# STM32L4x3 register map
File version: 1.5
CPU: CM4 r0p1, little endian, MPU, FPU, 4 interrupt priority bits
Registers are 32-bit, read-write, reset 0x0 unless marked. A register's access mark holds for its fields unless they carry their own. Offsets are from the block's base; [hi:lo] are bit positions; {n}, {i} and the like mark numbered series.

## CRS — Clock recovery system
Base 0x40006000
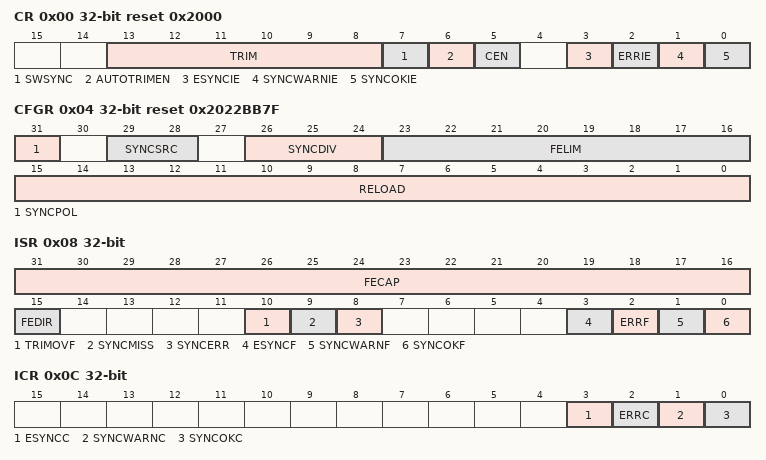
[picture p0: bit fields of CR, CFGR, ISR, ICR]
0x00 CR reset 0x2000 — control register
  [13:8] TRIM — HSI48 oscillator smooth trimming
  [7] SWSYNC — Generate software SYNC event
  [6] AUTOTRIMEN — Automatic trimming enable
  [5] CEN — Frequency error counter enable
  [3] ESYNCIE — Expected SYNC interrupt enable
  [2] ERRIE — Synchronization or trimming error interrupt enable
  [1] SYNCWARNIE — SYNC warning interrupt enable
  [0] SYNCOKIE — SYNC event OK interrupt enable
0x04 CFGR reset 0x2022BB7F — configuration register
  [31] SYNCPOL — SYNC polarity selection
  [29:28] SYNCSRC — SYNC signal source selection
  [26:24] SYNCDIV — SYNC divider
  [23:16] FELIM — Frequency error limit
  [15:0] RELOAD — Counter reload value
0x08 ISR ro — interrupt and status register
  [31:16] FECAP — Frequency error capture
  [15] FEDIR — Frequency error direction
  [10] TRIMOVF — Trimming overflow or underflow
  [9] SYNCMISS — SYNC missed
  [8] SYNCERR — SYNC error
  [3] ESYNCF — Expected SYNC flag
  [2] ERRF — Error flag
  [1] SYNCWARNF — SYNC warning flag
  [0] SYNCOKF — SYNC event OK flag
0x0C ICR — interrupt flag clear register
  [3] ESYNCC — Expected SYNC clear flag
  [2] ERRC — Error clear flag
  [1] SYNCWARNC — SYNC warning clear flag
  [0] SYNCOKC — SYNC event OK clear flag

## USB — Universal serial bus full-speed device interface
Base 0x40006C00
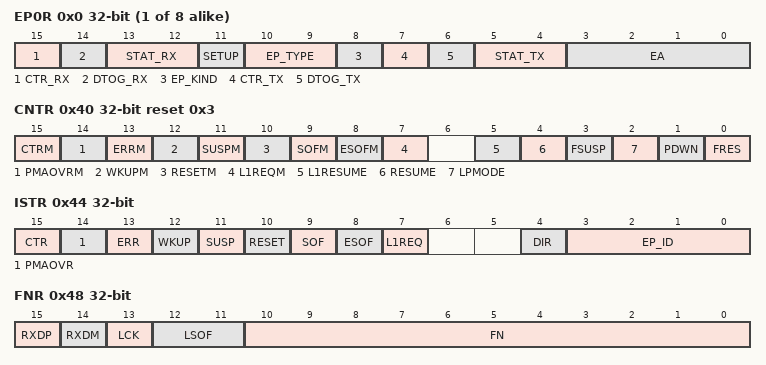
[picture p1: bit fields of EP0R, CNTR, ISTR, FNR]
{0x0+4i} EP{i}R (i=0..7) — endpoint {i} register
  [15] CTR_RX — Correct transfer for reception
  [14] DTOG_RX — Data Toggle, for reception transfers
  [13:12] STAT_RX — Status bits, for reception transfers
  [11] SETUP — Setup transaction completed
  [10:9] EP_TYPE — Endpoint type
  [8] EP_KIND — Endpoint kind
  [7] CTR_TX — Correct Transfer for transmission
  [6] DTOG_TX — Data Toggle, for transmission transfers
  [5:4] STAT_TX — Status bits, for transmission transfers
  [3:0] EA — Endpoint address
0x40 CNTR reset 0x3 — control register
  [15] CTRM — Correct transfer interrupt mask
  [14] PMAOVRM — Packet memory area over / underrun interrupt mask
  [13] ERRM — Error interrupt mask
  [12] WKUPM — Wakeup interrupt mask
  [11] SUSPM — Suspend mode interrupt mask
  [10] RESETM — USB reset interrupt mask
  [9] SOFM — Start of frame interrupt mask
  [8] ESOFM — Expected start of frame interrupt mask
  [7] L1REQM — LPM L1 state request interrupt mask
  [5] L1RESUME — LPM L1 Resume request
  [4] RESUME — Resume request
  [3] FSUSP — Force suspend
  [2] LPMODE — Low-power mode
  [1] PDWN — Power down
  [0] FRES — Force USB Reset
0x44 ISTR access per field — interrupt status register
  [15] CTR ro — Correct transfer
  [14] PMAOVR rw — Packet memory area over / underrun
  [13] ERR rw — Error
  [12] WKUP rw — Wakeup
  [11] SUSP rw — Suspend mode request
  [10] RESET rw — reset request
  [9] SOF rw — start of frame
  [8] ESOF rw — Expected start frame
  [7] L1REQ rw — LPM L1 state request
  [4] DIR ro — Direction of transaction
  [3:0] EP_ID ro — Endpoint Identifier
0x48 FNR ro — frame number register
  [15] RXDP — Receive data + line status
  [14] RXDM — Receive data - line status
  [13] LCK — Locked
  [12:11] LSOF — Lost SOF
  [10:0] FN — Frame number
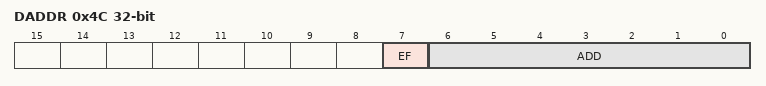
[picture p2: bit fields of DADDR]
0x4C DADDR — device address
  [7] EF — Enable function
  [6:0] ADD — Device address
0x50 BTABLE — Buffer table address
  [15:3] BTABLE — Buffer table

## DBGMCU — MCU debug component
Base 0xE0042000
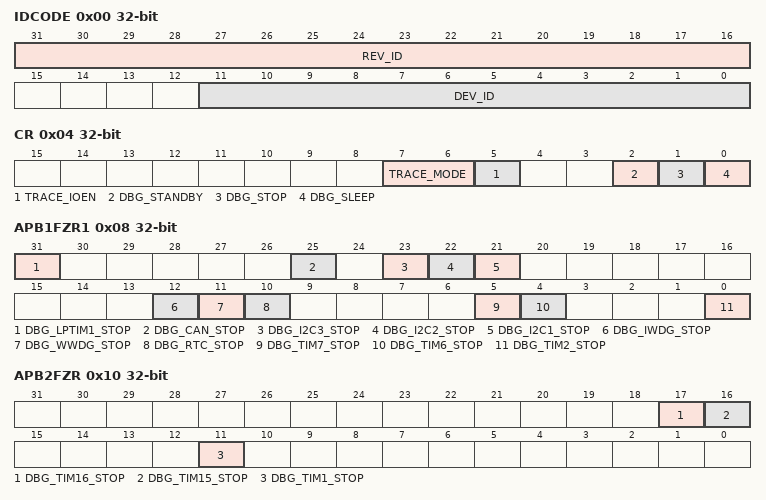
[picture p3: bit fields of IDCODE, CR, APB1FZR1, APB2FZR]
0x00 IDCODE ro — DBGMCU_IDCODE
  [31:16] REV_ID — Revision identifie
  [11:0] DEV_ID — Device identifier
0x04 CR — Debug MCU configuration register
  [7:6] TRACE_MODE — Trace pin assignment control
  [5] TRACE_IOEN — Trace pin assignment control
  [2] DBG_STANDBY — Debug Standby mode
  [1] DBG_STOP — Debug Stop mode
  [0] DBG_SLEEP — Debug Sleep mode
0x08 APB1FZR1 — Debug MCU APB1 freeze register1
  [31] DBG_LPTIM1_STOP — LPTIM1 counter stopped when core is halted
  [25] DBG_CAN_STOP — bxCAN stopped when core is halted
  [23] DBG_I2C3_STOP — I2C3 SMBUS timeout counter stopped when core is halted
  [22] DBG_I2C2_STOP — I2C2 SMBUS timeout counter stopped when core is halted
  [21] DBG_I2C1_STOP — I2C1 SMBUS timeout counter stopped when core is halted
  [12] DBG_IWDG_STOP — Independent watchdog counter stopped when core is halted
  [11] DBG_WWDG_STOP — Window watchdog counter stopped when core is halted
  [10] DBG_RTC_STOP — RTC counter stopped when core is halted
  [5] DBG_TIM7_STOP — TIM7 counter stopped when core is halted
  [4] DBG_TIM6_STOP — TIM6 counter stopped when core is halted
  [0] DBG_TIM2_STOP — TIM2 counter stopped when core is halted
0x0C APB1FZR2 — Debug MCU APB1 freeze register 2
  [5] DBG_LPTIM2_STOP — LPTIM2 counter stopped when core is halted
0x10 APB2FZR — Debug MCU APB2 freeze register
  [17] DBG_TIM16_STOP — TIM16 counter stopped when core is halted
  [16] DBG_TIM15_STOP — TIM15 counter stopped when core is halted
  [11] DBG_TIM1_STOP — TIM1 counter stopped when core is halted

## FPU — Floting point unit
Base 0xE000EF34
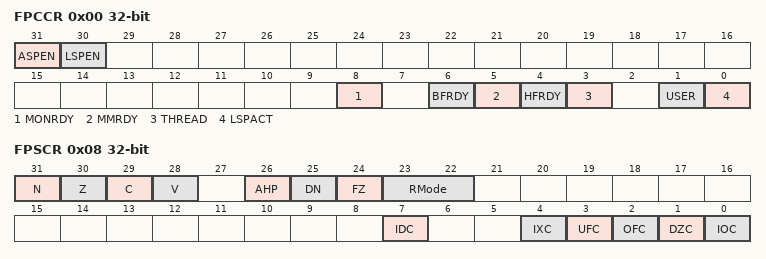
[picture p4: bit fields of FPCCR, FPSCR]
0x00 FPCCR — Floating-point context control register
  [31] ASPEN, [30] LSPEN, [8] MONRDY, [6] BFRDY, [5] MMRDY, [4] HFRDY, [3] THREAD, [1] USER, [0] LSPACT
0x04 FPCAR — Floating-point context address register
  [31:3] ADDRESS — Location of unpopulated floating-point
0x08 FPSCR — Floating-point status control register
  [31] N — Negative condition code flag
  [30] Z — Zero condition code flag
  [29] C — Carry condition code flag
  [28] V — Overflow condition code flag
  [26] AHP — Alternative half-precision control bit
  [25] DN — Default NaN mode control bit
  [24] FZ — Flush-to-zero mode control bit:
  [23:22] RMode — Rounding Mode control field
  [7] IDC — Input denormal cumulative exception bit.
  [4] IXC — Inexact cumulative exception bit
  [3] UFC — Underflow cumulative exception bit
  [2] OFC — Overflow cumulative exception bit
  [1] DZC — Division by zero cumulative exception bit.
  [0] IOC — Invalid operation cumulative exception bit

## MPU — Memory protection unit
Base 0xE000ED90
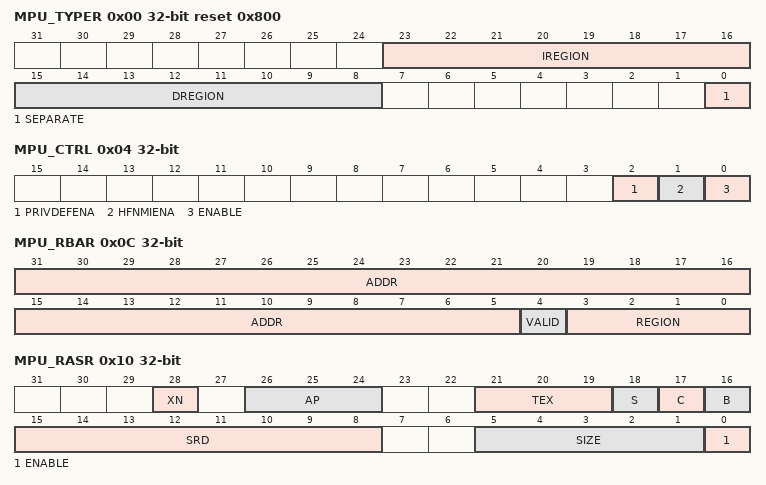
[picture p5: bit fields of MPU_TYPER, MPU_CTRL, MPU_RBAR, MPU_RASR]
0x00 MPU_TYPER ro reset 0x800 — MPU type register
  [23:16] IREGION — Number of MPU instruction regions
  [15:8] DREGION — Number of MPU data regions
  [0] SEPARATE — Separate flag
0x04 MPU_CTRL — MPU control register
  [2] PRIVDEFENA — Enable priviliged software access to default memory map
  [1] HFNMIENA — Enables the operation of MPU during hard fault
  [0] ENABLE — Enables the MPU
0x08 MPU_RNR — MPU region number register
  [7:0] REGION — MPU region
0x0C MPU_RBAR — MPU region base address register
  [31:5] ADDR — Region base address field
  [4] VALID — MPU region number valid
  [3:0] REGION — MPU region field
0x10 MPU_RASR — MPU region attribute and size register
  [28] XN — Instruction access disable bit
  [26:24] AP — Access permission
  [21:19] TEX — memory attribute
  [18] S — Shareable memory attribute
  [17] C — memory attribute
  [16] B — memory attribute
  [15:8] SRD — Subregion disable bits
  [5:1] SIZE — Size of the MPU protection region
  [0] ENABLE — Region enable bit.

## STK — SysTick timer
Base 0xE000E010
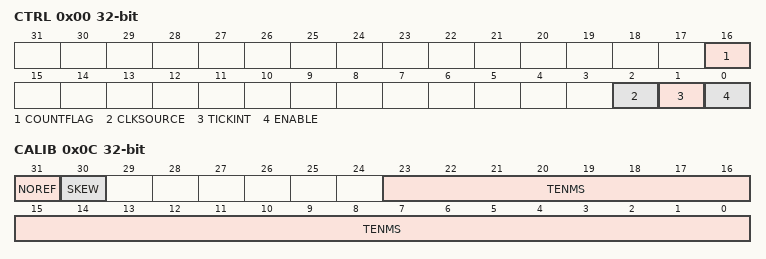
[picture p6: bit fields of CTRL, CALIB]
0x00 CTRL — SysTick control and status register
  [16] COUNTFLAG
  [2] CLKSOURCE — Clock source selection
  [1] TICKINT — SysTick exception request enable
  [0] ENABLE — Counter enable
0x04 LOAD — SysTick reload value register
  [23:0] RELOAD — RELOAD value
0x08 VAL — SysTick current value register
  [23:0] CURRENT — Current counter value
0x0C CALIB — SysTick calibration value register
  [31] NOREF — NOREF flag. Reads as zero
  [30] SKEW — SKEW flag: Indicates whether the TENMS value is exact
  [23:0] TENMS — Calibration value

## NVIC_STIR — Nested vectored interrupt controller
Base 0xE000EF00
0x00 STIR — Software trigger interrupt register
  [8:0] INTID — Software generated interrupt ID

## FPU_CPACR — Floating point unit CPACR
Base 0xE000ED88
0x00 CPACR — Coprocessor access control register
  [23:20] CP

## SCB_ACTRL — System control block ACTLR
Base 0xE000E008
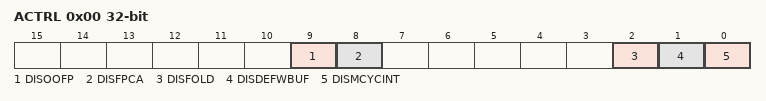
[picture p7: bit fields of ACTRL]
0x00 ACTRL — Auxiliary control register
  [9] DISOOFP, [8] DISFPCA, [2] DISFOLD, [1] DISDEFWBUF, [0] DISMCYCINT
